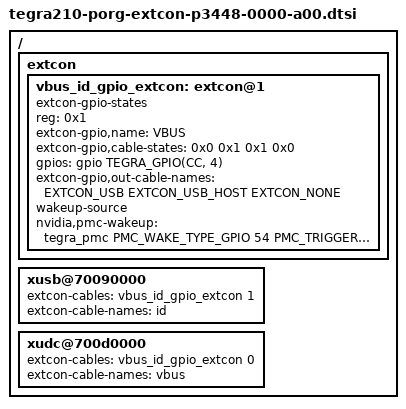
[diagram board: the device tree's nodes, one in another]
/*
 * Copyright (c) 2018-2019, NVIDIA CORPORATION.  All rights reserved.
 *
 * This program is free software; you can redistribute it and/or modify it
 * under the terms and conditions of the GNU General Public License,
 * version 2, as published by the Free Software Foundation.
 *
 * This program is distributed in the hope it will be useful, but WITHOUT
 * ANY WARRANTY; without even the implied warranty of MERCHANTABILITY or
 * FITNESS FOR A PARTICULAR PURPOSE.  See the GNU General Public License for
 * more details.
 */

#include "dt-bindings/extcon-ids.h"

/ {
	extcon {
		vbus_id_gpio_extcon: extcon@1 {
			compatible = "extcon-gpio-states";
			reg = <0x1>;
			extcon-gpio,name = "VBUS";
			extcon-gpio,cable-states = <
						0x0 0x1
						0x1 0x0>;
			gpios = <&gpio TEGRA_GPIO(CC, 4) 0>;
			extcon-gpio,out-cable-names = <EXTCON_USB EXTCON_USB_HOST EXTCON_NONE>;
			wakeup-source;
			#extcon-cells = <1>;
			nvidia,pmc-wakeup = <&tegra_pmc
				PMC_WAKE_TYPE_GPIO 54 PMC_TRIGGER_TYPE_NONE>;
		};
	};

	xusb@70090000 {
		extcon-cables = <&vbus_id_gpio_extcon 1>;
		extcon-cable-names = "id";
	};

	xudc@700d0000 {
		extcon-cables = <&vbus_id_gpio_extcon 0>;
		extcon-cable-names = "vbus";
	};

};
